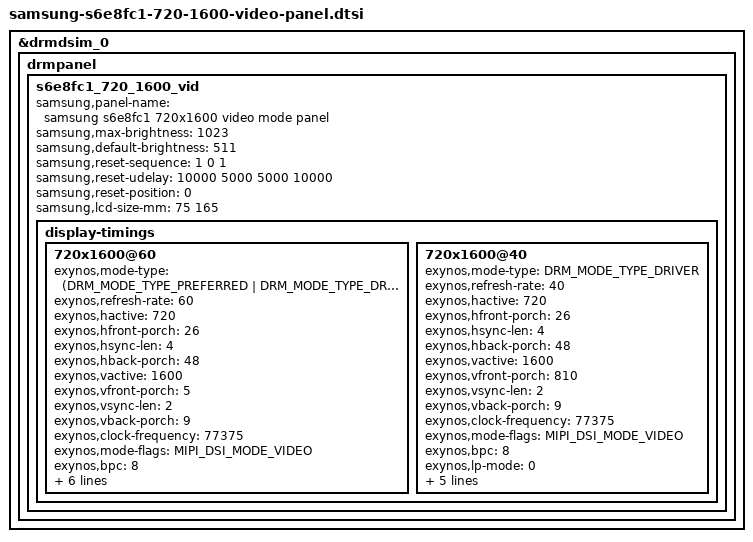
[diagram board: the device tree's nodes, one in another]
#include <dt-bindings/display/exynos-display.h>
#include <dt-bindings/display/exynos-mipi-display.h>

&drmdsim_0 {
	drmpanel {
		s6e8fc1_720_1600_vid: s6e8fc1_720_1600_vid {
			samsung,panel-name = "samsung s6e8fc1 720x1600 video mode panel";
			samsung,max-brightness = <1023>;
			samsung,default-brightness = <511>;

			samsung,reset-sequence = <1 0 1>;
			samsung,reset-udelay = <10000 5000 5000 10000>;
			samsung,reset-position = <0>;

			samsung,lcd-size-mm = <75 165>; /* width x height */

			display-timings {
				720x1600@60 {
					exynos,mode-type = <(DRM_MODE_TYPE_PREFERRED |
							DRM_MODE_TYPE_DRIVER)>;
					exynos,refresh-rate = <60>;
					exynos,hactive = <720>;
					exynos,hfront-porch = <26>;
					exynos,hsync-len = <4>;
					exynos,hback-porch = <48>;
					exynos,vactive = <1600>;
					exynos,vfront-porch = <5>;
					exynos,vsync-len = <2>;
					exynos,vback-porch = <9>;
					exynos,clock-frequency = <77375>;

					exynos,mode-flags = <MIPI_DSI_MODE_VIDEO>;
					exynos,bpc = <8>;
					exynos,lp-mode = <0>;
					exynos,dsc-en = <0>;

					exynos,on-cmds = <
						0x01 0x11 0x14
						0x03 0xF0 0x5A 0x5A 0x00
						0x03 0xFC 0x5A 0x5A 0x00
						0x0E 0xED 0x00 0x01 0x00 0x40 0x04 0x08 0xA8 0x84 0x4A 0x73 0x02 0x0A 0x00 0x00
						0x03 0xF1 0xA5 0xA5 0x00
						0x02 0x53 0x20 0x00
						0x07 0xB3 0x11 0x50 0xDD 0x0D 0xC0 0x0A 0x00
						0x03 0x51 0x03 0xFF 0x00
						0x02 0xF9 0x20 0x00
						0x03 0xF0 0xA5 0xA5 0x64
						>;
					exynos,disp-on-cmds = <
						0x01 0x29 0x00
						>;
					exynos,off-cmds = <
						0x01 0x10 0x00
						0x01 0x28 0x00
						>;
				};
				720x1600@40 {
					exynos,mode-type = <DRM_MODE_TYPE_DRIVER>;
					exynos,refresh-rate = <40>;
					exynos,hactive = <720>;
					exynos,hfront-porch = <26>;
					exynos,hsync-len = <4>;
					exynos,hback-porch = <48>;
					exynos,vactive = <1600>;
					exynos,vfront-porch = <810>;
					exynos,vsync-len = <2>;
					exynos,vback-porch = <9>;
					exynos,clock-frequency = <77375>;

					exynos,mode-flags = <MIPI_DSI_MODE_VIDEO>;
					exynos,bpc = <8>;
					exynos,lp-mode = <0>;
					exynos,dsc-en = <0>;

					exynos,on-cmds = <
						0x01 0x11 0x14
						0x03 0xF0 0x5A 0x5A 0x00
						0x03 0xFC 0x5A 0x5A 0x00
						0x0E 0xED 0x00 0x01 0x00 0x40 0x04 0x08 0xA8 0x84 0x4A 0x73 0x02 0x0A 0x00 0x00
						0x03 0xF1 0xA5 0xA5 0x00
						0x02 0x53 0x20 0x00
						0x07 0xB3 0x11 0x50 0xDD 0x0D 0xC0 0x0A 0x00
						0x03 0x51 0x03 0xFF 0x00
						0x02 0xF9 0x20 0x00
						0x03 0xF0 0xA5 0xA5 0x64
						>;
					exynos,disp-on-cmds = <
						0x01 0x29 0x00
						>;
					exynos,off-cmds = <
						0x01 0x10 0x00
						0x01 0x28 0x00
						>;
				};
			};
		};
	};
};
